# ATmega2561 device description
Architecture: AVR8; Family: megaAVR
Registers are 8-bit, access not given, no defined reset value unless marked. A register's access mark holds for its fields unless they carry their own. Offsets are from the block's base; [hi:lo] are bit positions.

## TC4 (TC16 module) — Timer/Counter, 16-bit
Instances: TC4 0x00
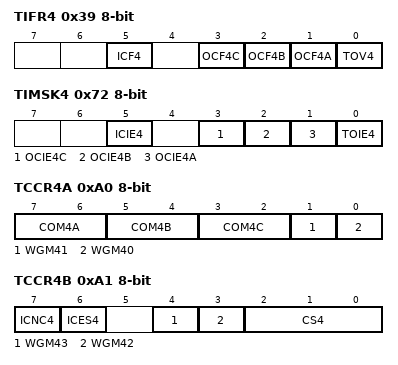
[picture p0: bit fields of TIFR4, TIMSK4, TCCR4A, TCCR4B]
0x39 TIFR4 — Timer/Counter4 Interrupt Flag register
  [5] ICF4 — Input Capture Flag 4
  [3] OCF4C — Output Compare Flag 4C
  [2] OCF4B — Output Compare Flag 4B
  [1] OCF4A — Output Compare Flag 4A
  [0] TOV4 — Timer/Counter4 Overflow Flag
0x72 TIMSK4 — Timer/Counter4 Interrupt Mask Register
  [5] ICIE4 — Timer/Counter4 Input Capture Interrupt Enable
  [3] OCIE4C — Timer/Counter4 Output Compare C Match Interrupt Enable
  [2] OCIE4B — Timer/Counter4 Output Compare B Match Interrupt Enable
  [1] OCIE4A — Timer/Counter4 Output Compare A Match Interrupt Enable
  [0] TOIE4 — Timer/Counter4 Overflow Interrupt Enable
0xA0 TCCR4A — Timer/Counter4 Control Register A
  [7:6] COM4A — Compare Output Mode 1A, bits
  [5:4] COM4B — Compare Output Mode 4B, bits
  [3:2] COM4C — Compare Output Mode 4C, bits
  [1] WGM41 — Waveform Generation Mode
  [0] WGM40 — Waveform Generation Mode
0xA1 TCCR4B — Timer/Counter4 Control Register B
  [7] ICNC4 — Input Capture 4 Noise Canceler
  [6] ICES4 — Input Capture 4 Edge Select
  [4] WGM43 (bit 2 of the value upward) — Waveform Generation Mode
  [3] WGM42 (bit 2 of the value upward) — Waveform Generation Mode
  [2:0] CS4 — Prescaler source of Timer/Counter 4
    0=No Clock Source (Stopped); 1=Running, No Prescaling; 2=Running, CLK/8; 3=Running, CLK/64; 4=Running, CLK/256; 5=Running, CLK/1024; 6=Running, ExtClk Tx Falling Edge; 7=Running, ExtClk Tx Rising Edge
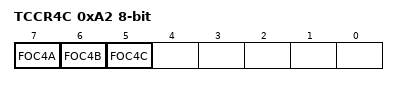
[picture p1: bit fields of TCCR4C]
0xA2 TCCR4C — Timer/Counter 4 Control Register C
  [7] FOC4A — Force Output Compare 4A
  [6] FOC4B — Force Output Compare 4B
  [5] FOC4C — Force Output Compare 4C
0xA4 TCNT4 16-bit — Timer/Counter4 Bytes
0xA6 ICR4 16-bit — Timer/Counter4 Input Capture Register Bytes
0xA8 OCR4A 16-bit — Timer/Counter4 Output Compare Register A Bytes
0xAA OCR4B 16-bit — Timer/Counter4 Output Compare Register B Bytes
0xAC OCR4C 16-bit — Timer/Counter4 Output Compare Register B Bytes

## TC3 (TC16 module) — Timer/Counter, 16-bit
Instances: TC3 0x00
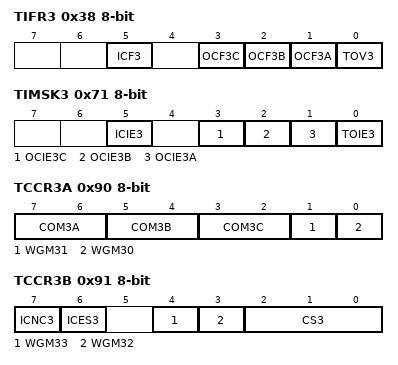
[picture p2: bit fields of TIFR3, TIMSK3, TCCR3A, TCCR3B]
0x38 TIFR3 — Timer/Counter3 Interrupt Flag register
  [5] ICF3 — Input Capture Flag 3
  [3] OCF3C — Output Compare Flag 3C
  [2] OCF3B — Output Compare Flag 3B
  [1] OCF3A — Output Compare Flag 3A
  [0] TOV3 — Timer/Counter3 Overflow Flag
0x71 TIMSK3 — Timer/Counter3 Interrupt Mask Register
  [5] ICIE3 — Timer/Counter3 Input Capture Interrupt Enable
  [3] OCIE3C — Timer/Counter3 Output Compare C Match Interrupt Enable
  [2] OCIE3B — Timer/Counter3 Output Compare B Match Interrupt Enable
  [1] OCIE3A — Timer/Counter3 Output Compare A Match Interrupt Enable
  [0] TOIE3 — Timer/Counter3 Overflow Interrupt Enable
0x90 TCCR3A — Timer/Counter3 Control Register A
  [7:6] COM3A — Compare Output Mode 1A, bits
  [5:4] COM3B — Compare Output Mode 3B, bits
  [3:2] COM3C — Compare Output Mode 3C, bits
  [1] WGM31 — Waveform Generation Mode
  [0] WGM30 — Waveform Generation Mode
0x91 TCCR3B — Timer/Counter3 Control Register B
  [7] ICNC3 — Input Capture 3 Noise Canceler
  [6] ICES3 — Input Capture 3 Edge Select
  [4] WGM33 (bit 2 of the value upward) — Waveform Generation Mode
  [3] WGM32 (bit 2 of the value upward) — Waveform Generation Mode
  [2:0] CS3 — Prescaler source of Timer/Counter 3
    0=No Clock Source (Stopped); 1=Running, No Prescaling; 2=Running, CLK/8; 3=Running, CLK/64; 4=Running, CLK/256; 5=Running, CLK/1024; 6=Running, ExtClk Tx Falling Edge; 7=Running, ExtClk Tx Rising Edge
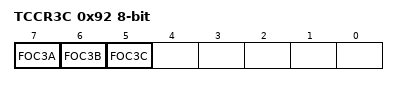
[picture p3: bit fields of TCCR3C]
0x92 TCCR3C — Timer/Counter 3 Control Register C
  [7] FOC3A — Force Output Compare 3A
  [6] FOC3B — Force Output Compare 3B
  [5] FOC3C — Force Output Compare 3C
0x94 TCNT3 16-bit — Timer/Counter3 Bytes
0x96 ICR3 16-bit — Timer/Counter3 Input Capture Register Bytes
0x98 OCR3A 16-bit — Timer/Counter3 Output Compare Register A Bytes
0x9A OCR3B 16-bit — Timer/Counter3 Output Compare Register B Bytes
0x9C OCR3C 16-bit — Timer/Counter3 Output Compare Register B Bytes
